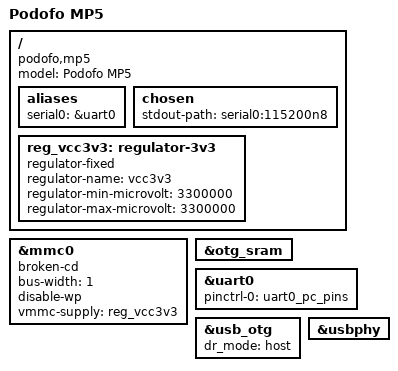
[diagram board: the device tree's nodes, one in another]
// SPDX-License-Identifier: (GPL-2.0+ OR MIT)
/*
 * Copyright 2022 Arm Ltd,
 * based on work:
 *   Copyright 2023 Damon Tarry <drt1245@gmail.com>
 */

/dts-v1/;
#include "suniv-f1c100s.dtsi"

#include <dt-bindings/gpio/gpio.h>

/ {
	model = "Podofo MP5";
	compatible = "podofo,mp5", "allwinner,suniv-f1c200s",
		     "allwinner,suniv-f1c100s";

	aliases {
		serial0 = &uart0;
	};

	chosen {
		stdout-path = "serial0:115200n8";
	};

	reg_vcc3v3: regulator-3v3 {
		compatible = "regulator-fixed";
		regulator-name = "vcc3v3";
		regulator-min-microvolt = <3300000>;
		regulator-max-microvolt = <3300000>;
	};
};

&mmc0 {
	broken-cd;
	bus-width = <1>;
	disable-wp;
	vmmc-supply = <&reg_vcc3v3>;
	status = "okay";
};

&otg_sram {
	status = "okay";
};

&uart0 {
	pinctrl-names = "default";
	pinctrl-0 = <&uart0_pc_pins>;
	status = "okay";
};

&usb_otg {
	dr_mode = "host";
	status = "okay";
};

&usbphy {
	status = "okay";
};
